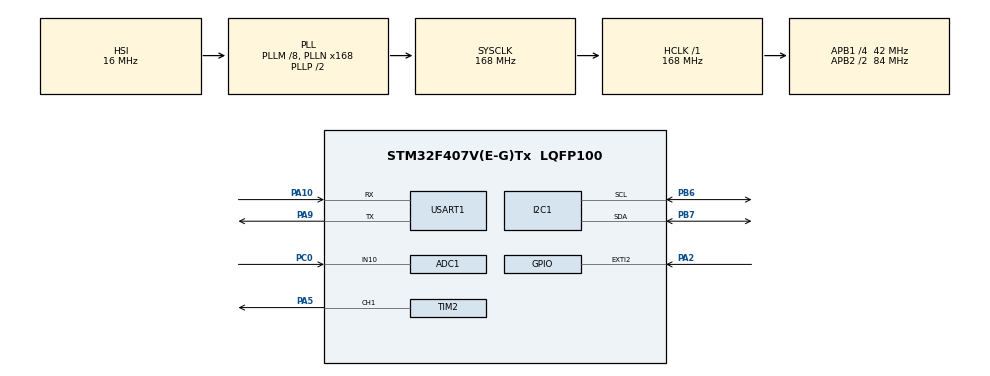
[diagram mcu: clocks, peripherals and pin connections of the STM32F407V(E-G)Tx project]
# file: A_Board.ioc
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ADC1.Channel-0\#ChannelRegularConversion=ADC_CHANNEL_10
ADC1.ContinuousConvMode=ENABLE
ADC1.DMAContinuousRequests=ENABLE
ADC1.NbrOfConversionFlag=1
ADC1.Rank-0\#ChannelRegularConversion=1
ADC1.SamplingTime-0\#ChannelRegularConversion=ADC_SAMPLETIME_3CYCLES
ADC1.ScanConvMode=ENABLE
ADC1.master=1
Dma.ADC1.0.Direction=DMA_PERIPH_TO_MEMORY
Dma.ADC1.0.FIFOMode=DMA_FIFOMODE_DISABLE
Dma.ADC1.0.Instance=DMA2_Stream0
Dma.ADC1.0.MemDataAlignment=DMA_MDATAALIGN_HALFWORD
Dma.ADC1.0.MemInc=DMA_MINC_ENABLE
Dma.ADC1.0.Mode=DMA_CIRCULAR
Dma.ADC1.0.PeriphDataAlignment=DMA_PDATAALIGN_HALFWORD
Dma.ADC1.0.PeriphInc=DMA_PINC_DISABLE
Dma.ADC1.0.Priority=DMA_PRIORITY_LOW
Dma.Request0=ADC1
Dma.Request1=USART1_RX
Dma.Request2=USART1_TX
Dma.USART1_RX.1.Direction=DMA_PERIPH_TO_MEMORY
Dma.USART1_RX.1.FIFOMode=DMA_FIFOMODE_DISABLE
Dma.USART1_RX.1.Instance=DMA2_Stream2
Dma.USART1_RX.1.MemDataAlignment=DMA_MDATAALIGN_BYTE
Dma.USART1_RX.1.MemInc=DMA_MINC_ENABLE
Dma.USART1_RX.1.Mode=DMA_NORMAL
Dma.USART1_RX.1.PeriphDataAlignment=DMA_PDATAALIGN_BYTE
Dma.USART1_RX.1.PeriphInc=DMA_PINC_DISABLE
Dma.USART1_RX.1.Priority=DMA_PRIORITY_LOW
Dma.USART1_TX.2.Direction=DMA_MEMORY_TO_PERIPH
Dma.USART1_TX.2.FIFOMode=DMA_FIFOMODE_DISABLE
Dma.USART1_TX.2.Instance=DMA2_Stream7
Dma.USART1_TX.2.MemDataAlignment=DMA_MDATAALIGN_BYTE
Dma.USART1_TX.2.MemInc=DMA_MINC_ENABLE
Dma.USART1_TX.2.Mode=DMA_NORMAL
Dma.USART1_TX.2.PeriphDataAlignment=DMA_PDATAALIGN_BYTE
Dma.USART1_TX.2.PeriphInc=DMA_PINC_DISABLE
Dma.USART1_TX.2.Priority=DMA_PRIORITY_LOW
Mcu.Family=STM32F4
Mcu.Name=STM32F407V(E-G)Tx
Mcu.Package=LQFP100
NVIC.ADC_IRQn=true\:4\:0\:true\:false\:true\:true\:true\:true
NVIC.DMA2_Stream0_IRQn=true\:0\:0\:false\:false\:true\:false\:true\:true
NVIC.DMA2_Stream2_IRQn=true\:0\:0\:false\:false\:true\:false\:true\:true
NVIC.DMA2_Stream7_IRQn=true\:0\:0\:false\:false\:true\:false\:true\:true
NVIC.EXTI2_IRQn=true\:3\:0\:true\:false\:true\:true\:true\:true
NVIC.PriorityGroup=NVIC_PRIORITYGROUP_4
NVIC.TIM3_IRQn=true\:2\:0\:true\:false\:true\:true\:true\:true
NVIC.USART1_IRQn=true\:1\:0\:true\:false\:true\:true\:true\:true
PC0.Signal=ADCx_IN10
PA10.Mode=Asynchronous
PA10.Signal=USART1_RX
PA13.Mode=Serial_Wire
PA13.Signal=SYS_JTMS-SWDIO
PA14.Mode=Serial_Wire
PA14.Signal=SYS_JTCK-SWCLK
PA2.GPIO_ModeDefaultEXTI=GPIO_MODE_IT_FALLING
PA2.GPIO_PuPd=GPIO_PULLUP
PA2.Signal=GPXTI2
PA5.Signal=S_TIM2_CH1_ETR
PA9.Mode=Asynchronous
PA9.Signal=USART1_TX
PB6.Mode=I2C
PB6.Signal=I2C1_SCL
PB7.Mode=I2C
PB7.Signal=I2C1_SDA
PH0-OSC_IN.Mode=HSE-External-Oscillator
PH0-OSC_IN.Signal=RCC_OSC_IN
PH1-OSC_OUT.Mode=HSE-External-Oscillator
PH1-OSC_OUT.Signal=RCC_OSC_OUT
ProjectManager.HeapSize=0x200
ProjectManager.StackSize=0x400
ProjectManager.TargetToolchain=MDK-ARM V5.32
RCC.48MHZClocksFreq_Value=84000000
RCC.AHBFreq_Value=168000000
RCC.APB1CLKDivider=RCC_HCLK_DIV4
RCC.APB1Freq_Value=42000000
RCC.APB1TimFreq_Value=84000000
RCC.APB2CLKDivider=RCC_HCLK_DIV2
RCC.APB2Freq_Value=84000000
RCC.APB2TimFreq_Value=168000000
RCC.CortexFreq_Value=168000000
RCC.HCLKFreq_Value=168000000
RCC.HSE_VALUE=25000000
RCC.HSI_VALUE=16000000
RCC.LSE_VALUE=32768
RCC.PLLM=8
RCC.PLLN=168
RCC.SYSCLKFreq_VALUE=168000000
RCC.SYSCLKSource=RCC_SYSCLKSOURCE_PLLCLK
RCC.VCOOutputFreq_Value=336000000
SH.ADCx_IN10.0=ADC1_IN10,IN10
SH.S_TIM2_CH1_ETR.0=TIM2_CH1,PWM Generation1 CH1
TIM2.AutoReloadPreload=TIM_AUTORELOAD_PRELOAD_ENABLE
TIM2.Channel-PWM\ Generation1\ CH1=TIM_CHANNEL_1
TIM2.Period=999
TIM2.Prescaler=83
TIM3.Period=999
TIM3.Prescaler=83
USART1.VirtualMode=VM_ASYNC
VP_TIM2_VS_ClockSourceINT.Mode=Internal
VP_TIM3_VS_ClockSourceINT.Mode=Internal
board=custom

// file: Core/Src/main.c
/* USER CODE BEGIN Header */
/**
  ******************************************************************************
  * @file           : main.c
  * @brief          : Main program body
  ******************************************************************************
  * @attention
  *
  * Copyright (c) 2026 STMicroelectronics.
  * All rights reserved.
  *
  * This software is licensed under terms that can be found in the LICENSE file
  * in the root directory of this software component.
  * If no LICENSE file comes with this software, it is provided AS-IS.
  *
  ******************************************************************************
  */
/* USER CODE END Header */
#include "main.h"
#include "adc.h"
#include "dma.h"
#include "i2c.h"
#include "tim.h"
#include "usart.h"
#include "gpio.h"

/* USER CODE BEGIN Includes */
#include "ssd1306.h"
#include "app_a.h"
/* USER CODE END Includes */

void SystemClock_Config(void);

int main(void)
{

  /* MCU Configuration--------------------------------------------------------*/

  /* Reset of all peripherals, Initializes the Flash interface and the Systick. */
  HAL_Init();

  /* Configure the system clock */
  SystemClock_Config();

  /* Initialize all configured peripherals */
  MX_GPIO_Init();
  MX_DMA_Init();
  MX_ADC1_Init();
  MX_I2C1_Init();
  MX_TIM2_Init();
  MX_TIM3_Init();
  MX_USART1_UART_Init();
  /* USER CODE BEGIN 2 */
  SSD1306_Init();
  AppA_Init();
  /* USER CODE END 2 */

  /* Infinite loop */
  while (1)
  {

    /* USER CODE BEGIN 3 */
    AppA_Process();
  }
  /* USER CODE END 3 */
}

void SystemClock_Config(void)
{
  RCC_OscInitTypeDef RCC_OscInitStruct = {0};
  RCC_ClkInitTypeDef RCC_ClkInitStruct = {0};

  /** Configure the main internal regulator output voltage
  */
  __HAL_RCC_PWR_CLK_ENABLE();
  __HAL_PWR_VOLTAGESCALING_CONFIG(PWR_REGULATOR_VOLTAGE_SCALE1);

  /** Initializes the RCC Oscillators according to the specified parameters
  * in the RCC_OscInitTypeDef structure.
  */
  RCC_OscInitStruct.OscillatorType = RCC_OSCILLATORTYPE_HSI;
  RCC_OscInitStruct.HSIState = RCC_HSI_ON;
  RCC_OscInitStruct.HSICalibrationValue = RCC_HSICALIBRATION_DEFAULT;
  RCC_OscInitStruct.PLL.PLLState = RCC_PLL_ON;
  RCC_OscInitStruct.PLL.PLLSource = RCC_PLLSOURCE_HSI;
  RCC_OscInitStruct.PLL.PLLM = 8;
  RCC_OscInitStruct.PLL.PLLN = 168;
  RCC_OscInitStruct.PLL.PLLP = RCC_PLLP_DIV2;
  RCC_OscInitStruct.PLL.PLLQ = 4;
  if (HAL_RCC_OscConfig(&RCC_OscInitStruct) != HAL_OK)
  {
    Error_Handler();
  }

  /** Initializes the CPU, AHB and APB buses clocks
  */
  RCC_ClkInitStruct.ClockType = RCC_CLOCKTYPE_HCLK|RCC_CLOCKTYPE_SYSCLK
                              |RCC_CLOCKTYPE_PCLK1|RCC_CLOCKTYPE_PCLK2;
  RCC_ClkInitStruct.SYSCLKSource = RCC_SYSCLKSOURCE_PLLCLK;
  RCC_ClkInitStruct.AHBCLKDivider = RCC_SYSCLK_DIV1;
  RCC_ClkInitStruct.APB1CLKDivider = RCC_HCLK_DIV4;
  RCC_ClkInitStruct.APB2CLKDivider = RCC_HCLK_DIV2;

  if (HAL_RCC_ClockConfig(&RCC_ClkInitStruct, FLASH_LATENCY_5) != HAL_OK)
  {
    Error_Handler();
  }
}

void Error_Handler(void)
{
  __disable_irq();
  while (1)
  {
  }
}
